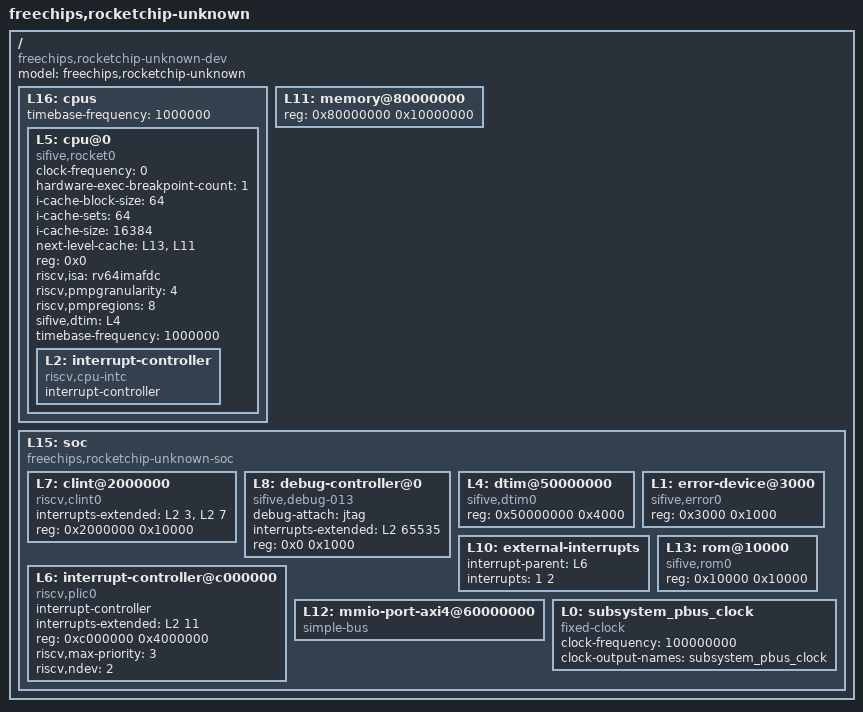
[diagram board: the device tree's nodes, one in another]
/dts-v1/;

/ {
	#address-cells = <1>;
	#size-cells = <1>;
	compatible = "freechips,rocketchip-unknown-dev";
	model = "freechips,rocketchip-unknown";
	L16: cpus {
		#address-cells = <1>;
		#size-cells = <0>;
		timebase-frequency = <1000000>;
		L5: cpu@0 {
			clock-frequency = <0>;
			compatible = "sifive,rocket0", "riscv";
			device_type = "cpu";
			hardware-exec-breakpoint-count = <1>;
			i-cache-block-size = <64>;
			i-cache-sets = <64>;
			i-cache-size = <16384>;
			next-level-cache = <&L13 &L11>;
			reg = <0x0>;
			riscv,isa = "rv64imafdc";
			riscv,pmpgranularity = <4>;
			riscv,pmpregions = <8>;
			sifive,dtim = <&L4>;
			status = "okay";
			timebase-frequency = <1000000>;
			L2: interrupt-controller {
				#interrupt-cells = <1>;
				compatible = "riscv,cpu-intc";
				interrupt-controller;
			};
		};
	};
	L11: memory@80000000 {
		device_type = "memory";
		reg = <0x80000000 0x10000000>;
	};
	L15: soc {
		#address-cells = <1>;
		#size-cells = <1>;
		compatible = "freechips,rocketchip-unknown-soc", "simple-bus";
		ranges;
		L7: clint@2000000 {
			compatible = "riscv,clint0";
			interrupts-extended = <&L2 3 &L2 7>;
			reg = <0x2000000 0x10000>;
			reg-names = "control";
		};
		L8: debug-controller@0 {
			compatible = "sifive,debug-013", "riscv,debug-013";
			debug-attach = "jtag";
			interrupts-extended = <&L2 65535>;
			reg = <0x0 0x1000>;
			reg-names = "control";
		};
		L4: dtim@50000000 {
			compatible = "sifive,dtim0";
			reg = <0x50000000 0x4000>;
			reg-names = "mem";
		};
		L1: error-device@3000 {
			compatible = "sifive,error0";
			reg = <0x3000 0x1000>;
		};
		L10: external-interrupts {
			interrupt-parent = <&L6>;
			interrupts = <1 2>;
		};
		L6: interrupt-controller@c000000 {
			#interrupt-cells = <1>;
			compatible = "riscv,plic0";
			interrupt-controller;
			interrupts-extended = <&L2 11>;
			reg = <0xc000000 0x4000000>;
			reg-names = "control";
			riscv,max-priority = <3>;
			riscv,ndev = <2>;
		};
		L12: mmio-port-axi4@60000000 {
			#address-cells = <1>;
			#size-cells = <1>;
			compatible = "simple-bus";
			ranges = <0x60000000 0x60000000 0x20000000>;
		};
		L13: rom@10000 {
			compatible = "sifive,rom0";
			reg = <0x10000 0x10000>;
			reg-names = "mem";
		};
		L0: subsystem_pbus_clock {
			#clock-cells = <0>;
			clock-frequency = <100000000>;
			clock-output-names = "subsystem_pbus_clock";
			compatible = "fixed-clock";
		};
	};
};
